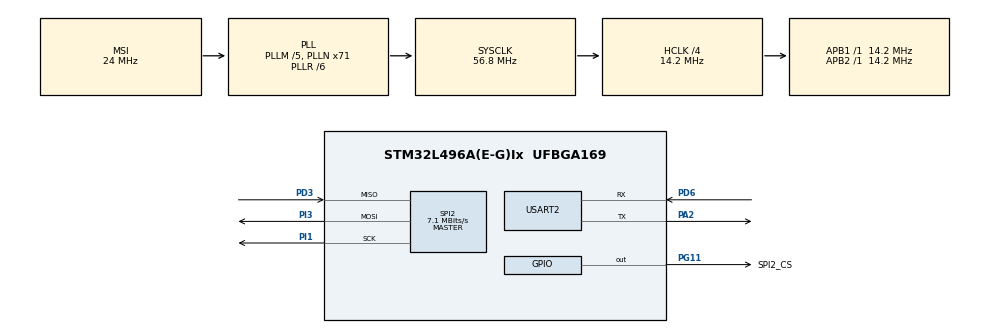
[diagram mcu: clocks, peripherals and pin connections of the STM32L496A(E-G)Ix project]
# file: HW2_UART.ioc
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Dma.Request0=SPI2_TX
Dma.Request1=SPI2_RX
Dma.SPI2_RX.1.Direction=DMA_PERIPH_TO_MEMORY
Dma.SPI2_RX.1.Instance=DMA1_Channel4
Dma.SPI2_RX.1.MemDataAlignment=DMA_MDATAALIGN_BYTE
Dma.SPI2_RX.1.MemInc=DMA_MINC_ENABLE
Dma.SPI2_RX.1.Mode=DMA_NORMAL
Dma.SPI2_RX.1.PeriphDataAlignment=DMA_PDATAALIGN_BYTE
Dma.SPI2_RX.1.PeriphInc=DMA_PINC_DISABLE
Dma.SPI2_RX.1.Priority=DMA_PRIORITY_LOW
Dma.SPI2_TX.0.Direction=DMA_MEMORY_TO_PERIPH
Dma.SPI2_TX.0.Instance=DMA1_Channel5
Dma.SPI2_TX.0.MemDataAlignment=DMA_MDATAALIGN_BYTE
Dma.SPI2_TX.0.MemInc=DMA_MINC_ENABLE
Dma.SPI2_TX.0.Mode=DMA_NORMAL
Dma.SPI2_TX.0.PeriphDataAlignment=DMA_PDATAALIGN_BYTE
Dma.SPI2_TX.0.PeriphInc=DMA_PINC_DISABLE
Dma.SPI2_TX.0.Priority=DMA_PRIORITY_LOW
Mcu.Family=STM32L4
Mcu.Name=STM32L496A(E-G)Ix
Mcu.Package=UFBGA169
NVIC.DMA1_Channel4_IRQn=true\:0\:0\:false\:false\:true\:false\:true\:true
NVIC.DMA1_Channel5_IRQn=true\:0\:0\:false\:false\:true\:false\:true\:true
NVIC.PriorityGroup=NVIC_PRIORITYGROUP_4
PA2.Mode=Asynchronous
PA2.Signal=USART2_TX
PD3.Mode=Full_Duplex_Master
PD3.Signal=SPI2_MISO
PD6.Mode=Asynchronous
PD6.Signal=USART2_RX
PG11.GPIO_Label=SPI2_CS
PG11.Signal=GPIO_Output
PI1.Mode=Full_Duplex_Master
PI1.Signal=SPI2_SCK
PI3.Mode=Full_Duplex_Master
PI3.Signal=SPI2_MOSI
ProjectManager.HeapSize=0x200
ProjectManager.StackSize=0x400
ProjectManager.TargetToolchain=STM32CubeIDE
RCC.ADCFreq_Value=48000000
RCC.AHBCLKDivider=RCC_SYSCLK_DIV4
RCC.AHBFreq_Value=14200000
RCC.APB1Freq_Value=14200000
RCC.APB1TimFreq_Value=14200000
RCC.APB2Freq_Value=14200000
RCC.APB2TimFreq_Value=14200000
RCC.CortexFreq_Value=14200000
RCC.HCLKFreq_Value=14200000
RCC.HSE_VALUE=8000000
RCC.HSI48_VALUE=48000000
RCC.HSI_VALUE=16000000
RCC.LSE_VALUE=32768
RCC.MSIClockRange=RCC_MSIRANGE_9
RCC.MSI_VALUE=24000000
RCC.PLLM=5
RCC.PLLN=71
RCC.PLLR=RCC_PLLR_DIV6
RCC.PLLSAI1N=20
RCC.SYSCLKFreq_VALUE=56800000
RCC.SYSCLKSource=RCC_SYSCLKSOURCE_PLLCLK
RCC.USBFreq_Value=48000000
RCC.VCOOutputFreq_Value=340800000
SPI2.CalculateBaudRate=7.1 MBits/s
SPI2.DataSize=SPI_DATASIZE_8BIT
SPI2.Direction=SPI_DIRECTION_2LINES
SPI2.Mode=SPI_MODE_MASTER
SPI2.VirtualType=VM_MASTER
USART2.VirtualMode-Asynchronous=VM_ASYNC
board=STM32L496G-DISCO

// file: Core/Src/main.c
/* USER CODE BEGIN Header */
/**
  ******************************************************************************
  * @file           : main.c
  * @brief          : Main program body
  ******************************************************************************
  * @attention
  *
  * Copyright (c) 2022 STMicroelectronics.
  * All rights reserved.
  *
  * This software is licensed under terms that can be found in the LICENSE file
  * in the root directory of this software component.
  * If no LICENSE file comes with this software, it is provided AS-IS.
  *
  ******************************************************************************
  */
/* USER CODE END Header */
#include "main.h"

/* USER CODE BEGIN Includes */
#include "stm32_ext_fram_dma.h"
#include <string.h>
/* USER CODE END Includes */

 SPI_HandleTypeDef hspi2;
DMA_HandleTypeDef hdma_spi2_tx;
DMA_HandleTypeDef hdma_spi2_rx;

UART_HandleTypeDef huart2;

void SystemClock_Config(void);
static void MX_GPIO_Init(void);
static void MX_DMA_Init(void);
static void MX_USART2_UART_Init(void);
static void MX_SPI2_Init(void);

int main(void)
{

  /* MCU Configuration--------------------------------------------------------*/

  /* Reset of all peripherals, Initializes the Flash interface and the Systick. */
  HAL_Init();

  /* Configure the system clock */
  SystemClock_Config();

  /* Initialize all configured peripherals */
  MX_GPIO_Init();
  MX_DMA_Init();
  MX_USART2_UART_Init();
  MX_SPI2_Init();
  /* USER CODE BEGIN 2 */
  FRAM_DMA_Init();

  uint8_t buffer[] = "Hello~~\r\n";
  HAL_UART_Transmit(&huart2, buffer, sizeof(buffer), HAL_MAX_DELAY);

  uint32_t addr = 0x000000;
  FRAM_DMA_Write(addr, buffer, sizeof(buffer));

  memset(buffer, 0, sizeof(buffer));
  FRAM_DMA_Read(addr, buffer, sizeof(buffer));
  /* USER CODE END 2 */

  /* Infinite loop */
  while (1)
  {

  }
}

void SystemClock_Config(void)
{
  RCC_OscInitTypeDef RCC_OscInitStruct = {0};
  RCC_ClkInitTypeDef RCC_ClkInitStruct = {0};

  /** Configure the main internal regulator output voltage
  */
  if (HAL_PWREx_ControlVoltageScaling(PWR_REGULATOR_VOLTAGE_SCALE1) != HAL_OK)
  {
    Error_Handler();
  }

  /** Initializes the RCC Oscillators according to the specified parameters
  * in the RCC_OscInitTypeDef structure.
  */
  RCC_OscInitStruct.OscillatorType = RCC_OSCILLATORTYPE_MSI;
  RCC_OscInitStruct.MSIState = RCC_MSI_ON;
  RCC_OscInitStruct.MSICalibrationValue = 0;
  RCC_OscInitStruct.MSIClockRange = RCC_MSIRANGE_9;
  RCC_OscInitStruct.PLL.PLLState = RCC_PLL_ON;
  RCC_OscInitStruct.PLL.PLLSource = RCC_PLLSOURCE_MSI;
  RCC_OscInitStruct.PLL.PLLM = 5;
  RCC_OscInitStruct.PLL.PLLN = 71;
  RCC_OscInitStruct.PLL.PLLP = RCC_PLLP_DIV2;
  RCC_OscInitStruct.PLL.PLLQ = RCC_PLLQ_DIV2;
  RCC_OscInitStruct.PLL.PLLR = RCC_PLLR_DIV6;
  if (HAL_RCC_OscConfig(&RCC_OscInitStruct) != HAL_OK)
  {
    Error_Handler();
  }

  /** Initializes the CPU, AHB and APB buses clocks
  */
  RCC_ClkInitStruct.ClockType = RCC_CLOCKTYPE_HCLK|RCC_CLOCKTYPE_SYSCLK
                              |RCC_CLOCKTYPE_PCLK1|RCC_CLOCKTYPE_PCLK2;
  RCC_ClkInitStruct.SYSCLKSource = RCC_SYSCLKSOURCE_PLLCLK;
  RCC_ClkInitStruct.AHBCLKDivider = RCC_SYSCLK_DIV4;
  RCC_ClkInitStruct.APB1CLKDivider = RCC_HCLK_DIV1;
  RCC_ClkInitStruct.APB2CLKDivider = RCC_HCLK_DIV1;

  if (HAL_RCC_ClockConfig(&RCC_ClkInitStruct, FLASH_LATENCY_0) != HAL_OK)
  {
    Error_Handler();
  }
}

static void MX_SPI2_Init(void)
{

  /* SPI2 parameter configuration*/
  hspi2.Instance = SPI2;
  hspi2.Init.Mode = SPI_MODE_MASTER;
  hspi2.Init.Direction = SPI_DIRECTION_2LINES;
  hspi2.Init.DataSize = SPI_DATASIZE_8BIT;
  hspi2.Init.CLKPolarity = SPI_POLARITY_LOW;
  hspi2.Init.CLKPhase = SPI_PHASE_1EDGE;
  hspi2.Init.NSS = SPI_NSS_SOFT;
  hspi2.Init.BaudRatePrescaler = SPI_BAUDRATEPRESCALER_2;
  hspi2.Init.FirstBit = SPI_FIRSTBIT_MSB;
  hspi2.Init.TIMode = SPI_TIMODE_DISABLE;
  hspi2.Init.CRCCalculation = SPI_CRCCALCULATION_DISABLE;
  hspi2.Init.CRCPolynomial = 7;
  hspi2.Init.CRCLength = SPI_CRC_LENGTH_DATASIZE;
  hspi2.Init.NSSPMode = SPI_NSS_PULSE_ENABLE;
  if (HAL_SPI_Init(&hspi2) != HAL_OK)
  {
    Error_Handler();
  }

}

static void MX_USART2_UART_Init(void)
{

  huart2.Instance = USART2;
  huart2.Init.BaudRate = 115200;
  huart2.Init.WordLength = UART_WORDLENGTH_8B;
  huart2.Init.StopBits = UART_STOPBITS_1;
  huart2.Init.Parity = UART_PARITY_NONE;
  huart2.Init.Mode = UART_MODE_TX_RX;
  huart2.Init.HwFlowCtl = UART_HWCONTROL_NONE;
  huart2.Init.OverSampling = UART_OVERSAMPLING_16;
  huart2.Init.OneBitSampling = UART_ONE_BIT_SAMPLE_DISABLE;
  huart2.AdvancedInit.AdvFeatureInit = UART_ADVFEATURE_NO_INIT;
  if (HAL_UART_Init(&huart2) != HAL_OK)
  {
    Error_Handler();
  }

}

static void MX_DMA_Init(void)
{

  /* DMA controller clock enable */
  __HAL_RCC_DMA1_CLK_ENABLE();

  /* DMA interrupt init */
  /* DMA1_Channel4_IRQn interrupt configuration */
  HAL_NVIC_SetPriority(DMA1_Channel4_IRQn, 0, 0);
  HAL_NVIC_EnableIRQ(DMA1_Channel4_IRQn);
  /* DMA1_Channel5_IRQn interrupt configuration */
  HAL_NVIC_SetPriority(DMA1_Channel5_IRQn, 0, 0);
  HAL_NVIC_EnableIRQ(DMA1_Channel5_IRQn);

}

static void MX_GPIO_Init(void)
{
  GPIO_InitTypeDef GPIO_InitStruct = {0};

  /* GPIO Ports Clock Enable */
  __HAL_RCC_GPIOI_CLK_ENABLE();
  __HAL_RCC_GPIOG_CLK_ENABLE();
  HAL_PWREx_EnableVddIO2();
  __HAL_RCC_GPIOD_CLK_ENABLE();
  __HAL_RCC_GPIOA_CLK_ENABLE();

  /*Configure GPIO pin Output Level */
  HAL_GPIO_WritePin(SPI2_CS_GPIO_Port, SPI2_CS_Pin, GPIO_PIN_RESET);

  /*Configure GPIO pin : SPI2_CS_Pin */
  GPIO_InitStruct.Pin = SPI2_CS_Pin;
  GPIO_InitStruct.Mode = GPIO_MODE_OUTPUT_PP;
  GPIO_InitStruct.Pull = GPIO_NOPULL;
  GPIO_InitStruct.Speed = GPIO_SPEED_FREQ_LOW;
  HAL_GPIO_Init(SPI2_CS_GPIO_Port, &GPIO_InitStruct);

}

void Error_Handler(void)
{
  __disable_irq();
  while (1)
  {
  }
}
